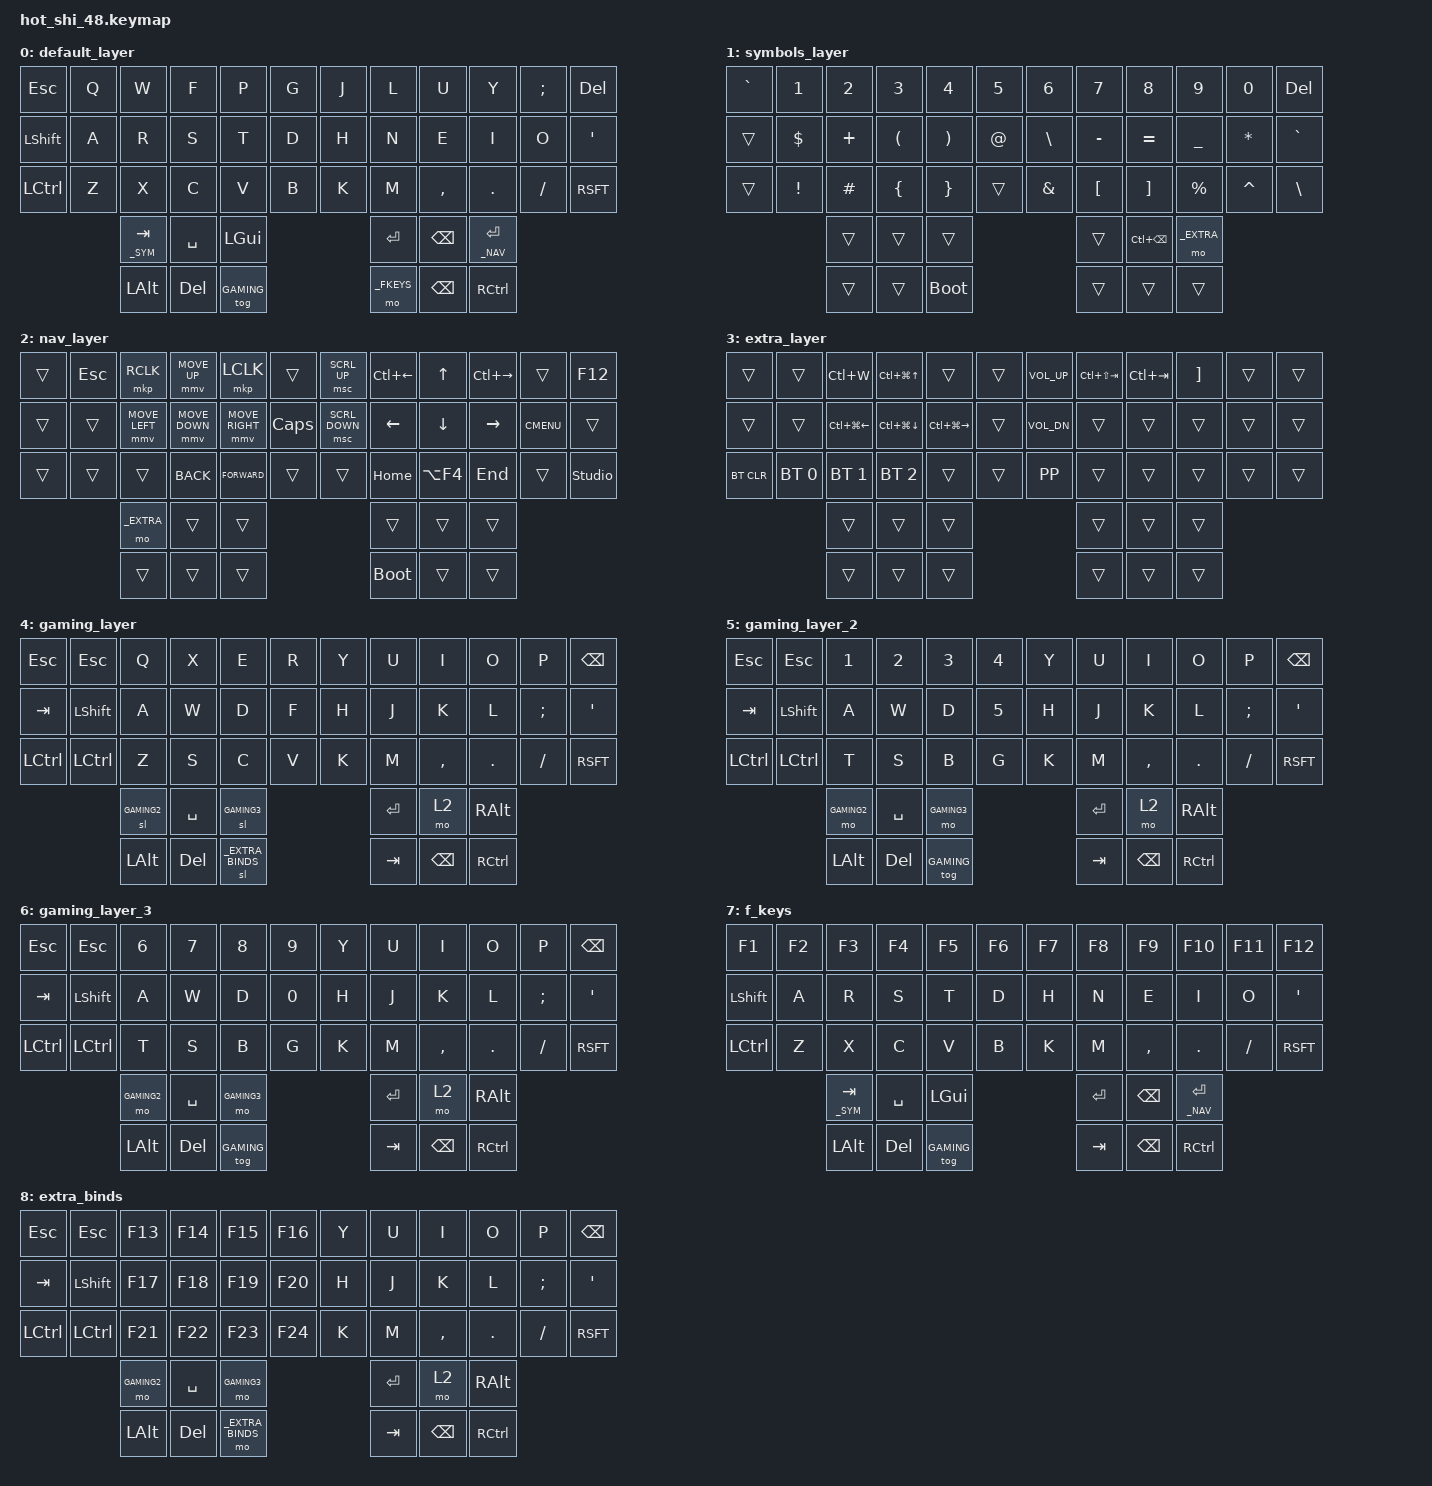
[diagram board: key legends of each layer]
#include <behaviors.dtsi>
#include <dt-bindings/zmk/keys.h>
#include <dt-bindings/zmk/bt.h>
#include <dt-bindings/zmk/mouse.h>
#define ZMK_POINTING_DEFAULT_MOVE_VAL 2500  // default: 600
#define ZMK_POINTING_DEFAULT_SCRL_VAL 35    // default: 10
#include <dt-bindings/zmk/pointing.h>


// Layer definitions
#define _BASE 0
#define _SYM  1
#define _NAV  2
#define _EXTRA 3
#define _GAMING 4
#define _GAMING2 5
#define _GAMING3 6
#define _FKEYS 7
#define _EXTRA_BINDS 8

// Define a tapping term for our Layer-Tap keys.
#define TAPPING_TERM 200
// Define a quick tapping term for combos.
#define COMBO_TERM 40

/ {
    behaviors {
        lt: layer_tap {
            compatible = "zmk,behavior-hold-tap";
            flavor = "hold-preferred";
            tapping-term-ms = <200>;
            bindings = <&mo>, <&kp>;
            display-name = "Layer-Tap";
        };
    };
combos {
        
        compatible = "zmk,combos";

        combo_win_o {
            timeout-ms = <23>;
            // triggers one time shift when pressing N and backspace
            key-positions = <22 40>;
            bindings = <&sk LGUI>;
            layers = <_BASE>;
        };

        combo_alt_i {
            timeout-ms = <23>;
            // triggers one time shift when pressing N and backspace
            key-positions = <21 40>;
            bindings = <&sk LALT>;
            layers = <_BASE>;
        };
        
        combo_shift_e {
            timeout-ms = <23>;
            // triggers one time shift when pressing N and backspace
            key-positions = <20 40>;
            bindings = <&sk LSHIFT>;
            layers = <_BASE>;
        };

        combo_ctrl_n {
            timeout-ms = <23>;
            // triggers one time shift when pressing N and backspace
            key-positions = <19 40>;
            bindings = <&sk LCTRL>;
            layers = <_BASE>;
        };



        combo_win_a {
            timeout-ms = <23>;
            // triggers one time shift when pressing N and backspace
            key-positions = <13 37>;
            bindings = <&sk LGUI>;
            layers = <_BASE>;
        };

        combo_alt_r {
            timeout-ms = <23>;
            // triggers one time shift when pressing N and backspace
            key-positions = <14 37>;
            bindings = <&sk LALT>;
            layers = <_BASE>;
        };
        
        combo_shift_s {
            timeout-ms = <23>;
            // triggers one time shift when pressing N and backspace
            key-positions = <15 37>;
            bindings = <&sk LSHIFT>;
            layers = <_BASE>;
        };

        combo_ctrl_t {
            timeout-ms = <23>;
            // triggers one time shift when pressing N and backspace
            key-positions = <16 37>;
            bindings = <&sk LCTRL>;
            layers = <_BASE>;
        };

        gaming_layer_toggle {
            timeout-ms = <60>;
            key-positions = <36 42>; // space + button underneath
            bindings = <&tog _GAMING>;
            layers = <_BASE _GAMING>;
        };
        extra_binds_momentary_combo {
            timeout-ms = <60>;
            key-positions = <37 43>; // gaming3 + extra_binds sticky
            bindings = <&mo _EXTRA_BINDS>;
            layers = <_GAMING>;
        };
    };


    keymap {
        compatible = "zmk,keymap";

        default_layer {
            bindings = <
                &kp ESC   &kp Q  &kp W  &kp F  &kp P  &kp G      &kp J  &kp L  &kp U     &kp Y    &kp SEMI  &kp DEL
                &kp LSHFT &kp A  &kp R  &kp S  &kp T  &kp D      &kp H  &kp N  &kp E     &kp I    &kp O     &kp SQT
                &kp LCTRL &kp Z  &kp X  &kp C  &kp V  &kp B      &kp K  &kp M  &kp COMMA &kp DOT  &kp FSLH  &kp RSFT
                
                                &lt _SYM TAB  &kp SPACE  &kp LGUI      &kp RET   &kp BSPC &lt _NAV ENTER
                                &kp LALT  &kp DEL &tog _GAMING      &mo _FKEYS   &kp BSPC &kp RCTRL
            >;
        };


         symbols_layer {
            bindings = <
                &kp GRAVE   &kp N1   &kp N2   &kp N3   &kp N4   &kp N5      &kp N6 &kp N7 &kp N8  &kp N9   &kp N0   &kp DEL
                &trans      &kp DLLR &kp PLUS &kp LPAR &kp RPAR &kp AT      &kp BSLH &kp MINUS &kp EQUAL &kp UNDER &kp STAR &kp GRAVE
                &trans &kp EXCL &kp HASH &kp LBRC &kp RBRC &trans      &kp AMPS &kp LBKT  &kp RBKT  &kp PRCNT   &kp CARET   &kp BSLH

                                                &trans  &trans &trans       &trans  &kp LC(BSPC)   &mo _EXTRA
                                                &trans  &trans &bootloader       &trans  &trans   &trans
            >;
        };

        nav_layer {
            bindings = <
                &trans    &kp ESC   &mkp RCLK       &mmv MOVE_UP    &mkp LCLK       &trans      &msc SCRL_UP &kp LC(LEFT) &kp UP &kp LC(RIGHT) &trans &kp F12 
                &trans    &trans    &mmv MOVE_LEFT  &mmv MOVE_DOWN  &mmv MOVE_RIGHT &kp CAPS      &msc SCRL_DOWN &kp LEFT &kp DOWN &kp RIGHT &kp K_CMENU &trans
                &trans    &trans    &trans          &kp K_BACK          &kp K_FORWARD           &trans      &trans &kp HOME  &kp LA(F4) &kp END &trans  &studio_unlock

                                                &mo _EXTRA    &trans    &trans                  &trans  &trans   &trans
                                                &trans    &trans    &trans                      &bootloader  &trans   &trans
            >;
        };

        extra_layer {
            bindings = <
                &trans    &trans &kp LC(W)          &kp LC(LG(UP))   &trans             &trans      &kp C_VOL_UP &kp LC(LS(TAB))  &kp LC(TAB) &kp RBKT &trans  &trans
                &trans    &trans &kp LC(LG(LEFT))   &kp LC(LG(DOWN)) &kp LC(LG(RIGHT))  &trans      &kp C_VOL_DN &trans &trans &trans &trans &trans
                &bt BT_CLR &bt BT_SEL 0 &bt BT_SEL 1 &bt BT_SEL 2 &trans &trans                     &kp K_PP &trans &trans &trans &trans &trans

                                                        &trans  &trans  &trans                      &trans  &trans   &trans
                                                        &trans  &trans  &trans                      &trans  &trans   &trans
            >;
        };
        
        gaming_layer {
            bindings = <
                &kp ESC   &kp ESC  &kp Q  &kp X  &kp E  &kp R      &kp Y  &kp U  &kp I     &kp O    &kp P     &kp BSPC
                &kp TAB &kp LSHFT  &kp A  &kp W  &kp D  &kp F      &kp H  &kp J  &kp K     &kp L    &kp SEMI  &kp SQT
                &kp LCTRL &kp LCTRL  &kp Z  &kp S  &kp C  &kp V      &kp K  &kp M  &kp COMMA &kp DOT  &kp FSLH  &kp RSFT

                                 &sl _GAMING2  &kp SPACE  &sl _GAMING3      &kp RET   &mo 2    &kp RALT
                                 &kp LALT  &kp DEL &sl _EXTRA_BINDS      &kp TAB   &kp BSPC &kp RCTRL
            >;
        };

        gaming_layer_2 {
            bindings = <
                &kp ESC   &kp ESC  &kp N1  &kp N2  &kp N3  &kp N4      &kp Y  &kp U  &kp I     &kp O    &kp P     &kp BSPC
                &kp TAB &kp LSHFT  &kp A  &kp W  &kp D  &kp N5      &kp H  &kp J  &kp K     &kp L    &kp SEMI  &kp SQT
                &kp LCTRL &kp LCTRL  &kp T  &kp S  &kp B  &kp G      &kp K  &kp M  &kp COMMA &kp DOT  &kp FSLH  &kp RSFT

                                 &mo _GAMING2  &kp SPACE  &mo _GAMING3      &kp RET   &mo 2    &kp RALT
                                 &kp LALT  &kp DEL &tog _GAMING      &kp TAB   &kp BSPC &kp RCTRL
            >;
        };

        gaming_layer_3 {
            bindings = <
                &kp ESC   &kp ESC  &kp N6  &kp N7  &kp N8  &kp N9      &kp Y  &kp U  &kp I     &kp O    &kp P     &kp BSPC
                &kp TAB  &kp LSHFT  &kp A  &kp W  &kp D  &kp N0      &kp H  &kp J  &kp K     &kp L    &kp SEMI  &kp SQT
                &kp LCTRL &kp LCTRL  &kp T  &kp S  &kp B  &kp G      &kp K  &kp M  &kp COMMA &kp DOT  &kp FSLH  &kp RSFT

                                 &mo _GAMING2  &kp SPACE  &mo _GAMING3      &kp RET   &mo 2    &kp RALT
                                 &kp LALT  &kp DEL &tog _GAMING      &kp TAB   &kp BSPC &kp RCTRL
            >;
        };

        f_keys {
            bindings = <
                &kp F1   &kp F2  &kp F3  &kp F4  &kp F5  &kp F6      &kp F7  &kp F8  &kp F9     &kp F10    &kp F11  &kp F12
                &kp LSHFT &kp A  &kp R  &kp S  &kp T  &kp D      &kp H  &kp N  &kp E     &kp I    &kp O     &kp SQT
                &kp LCTRL &kp Z  &kp X  &kp C  &kp V  &kp B      &kp K  &kp M  &kp COMMA &kp DOT  &kp FSLH  &kp RSFT
                
                                &lt _SYM TAB  &kp SPACE  &kp LGUI      &kp RET   &kp BSPC &lt _NAV ENTER
                                &kp LALT  &kp DEL &tog _GAMING      &kp TAB   &kp BSPC &kp RCTRL
            >;

       };

       extra_binds {
            bindings = <
                &kp ESC   &kp ESC  &kp F13  &kp F14  &kp F15  &kp F16      &kp Y  &kp U  &kp I     &kp O    &kp P     &kp BSPC
                &kp TAB  &kp LSHFT  &kp F17  &kp F18  &kp F19  &kp F20      &kp H  &kp J  &kp K     &kp L    &kp SEMI  &kp SQT
                &kp LCTRL &kp LCTRL  &kp F21  &kp F22  &kp F23  &kp F24      &kp K  &kp M  &kp COMMA &kp DOT  &kp FSLH  &kp RSFT

                                 &mo _GAMING2  &kp SPACE  &mo _GAMING3      &kp RET   &mo 2    &kp RALT
                                 &kp LALT  &kp DEL &mo _EXTRA_BINDS      &kp TAB   &kp BSPC &kp RCTRL
            >;
        };
    };
};
